# MU3E_MTS_PROCESSOR register map
Vendor: Mu3e; Series: MU3E_FPGA_IP; File version: 26.6.0.0716
CMSIS-SVD description of the exact MuTRiG timestamp processor CSR window for the optional external epoch-reset and 48-bit timestamp, arrival, and latency sideband release.
Registers are 32-bit, read-only, reset 0x0 unless marked. A register's access mark holds for its fields unless they carry their own. Offsets are from the block's base; lines under a group give offsets from that group; [hi:lo] are bit positions; {n}, {i} and the like mark numbered series; 'fields as' and 'values as' point back to an identical list; <NAME> marks a mode.

## Memory map
0x00000000 MTS_PROCESSOR_CSR size 0x20 — Relative CSR aperture for the MuTRiG timestamp processor.

## MTS_PROCESSOR_CSR — Relative CSR aperture for the MuTRiG timestamp processor.
Base 0x00000000
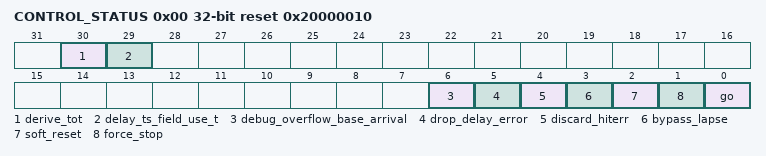
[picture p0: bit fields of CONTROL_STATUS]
0x00 CONTROL_STATUS rw reset 0x20000010 — Datapath controls and live RUNNING status. Bit 6 is a debug coordinate selector and must remain clear for physical hit-lifetime measurements.
  [30] derive_tot — Enable long-hit E-minus-T derivation.
  [29] delay_ts_field_use_t — Use T rather than E timestamp for delay classification.
  [6] debug_overflow_base_arrival — Debug only: select divided overflow-base arrival. The resulting signed latency is a phase coordinate, not physical lifetime.
  [5] drop_delay_error — Drop Type1 beats marked with a timestamp-delay error; clear forwards the marked beat.
  [4] discard_hiterr — Reject Type0 beats carrying the configured hit-error bit.
  [3] bypass_lapse — Bypass MTS-to-GTS lapse correction for raw-counter debug.
  [2] soft_reset — Self-clearing reset of counters and in-flight processing.
  [1] force_stop — Block new datapath output in every run state.
  [0] go — Write-enable datapath generation; readback is the live RUNNING indication.
0x04 DISCARD_HIT_COUNTER — Number of input hits rejected by the hit-error policy.
  [31:0] discard_hit_count — Discarded input-hit count.
0x08 EXPECTED_LATENCY_8NS rw reset 0x7D0 — Upper bound for the legacy delay-error classifier, in 8 ns ticks.
  [31:0] expected_latency — Configured delay-error window; default 2000 ticks.
0x0C TOTAL_HIT_COUNT_HI — Upper 16 bits of the 48-bit Type0 ingress-hit counter.
  [15:0] total_hit_count_hi — Ingress-hit count bits 47 through 32.
0x10 TOTAL_HIT_COUNT_LO — Lower 32 bits of the 48-bit Type0 ingress-hit counter.
  [31:0] total_hit_count_lo — Ingress-hit count bits 31 through 0.
